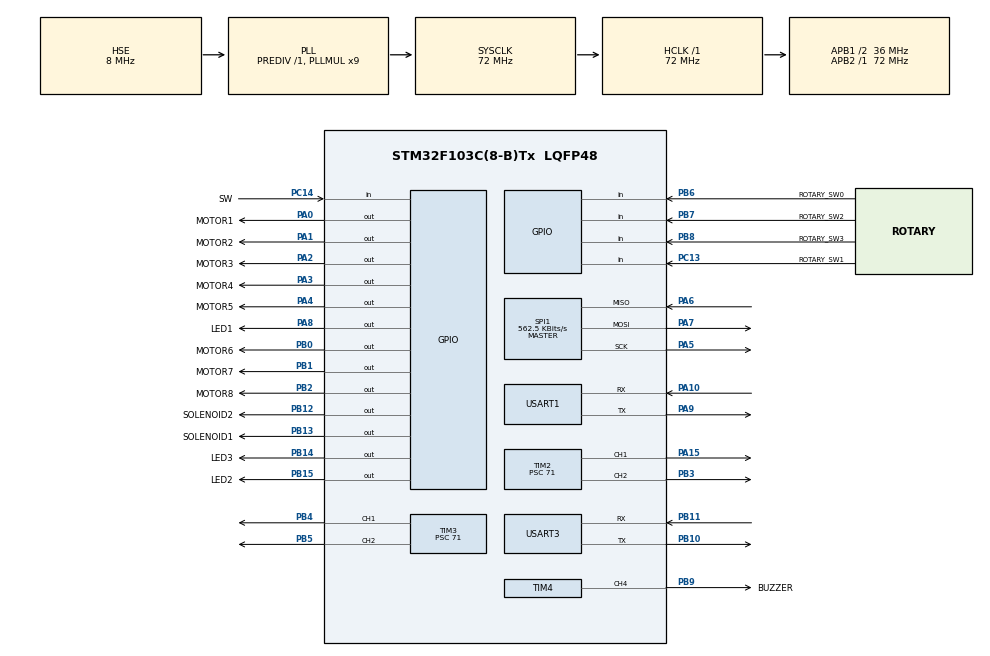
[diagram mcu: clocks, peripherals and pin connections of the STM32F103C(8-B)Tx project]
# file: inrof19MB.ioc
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Dma.Request0=USART3_RX
Dma.Request1=USART3_TX
Dma.Request2=USART1_RX
Dma.Request3=USART1_TX
Dma.USART1_RX.2.Direction=DMA_PERIPH_TO_MEMORY
Dma.USART1_RX.2.Instance=DMA1_Channel5
Dma.USART1_RX.2.MemDataAlignment=DMA_MDATAALIGN_BYTE
Dma.USART1_RX.2.MemInc=DMA_MINC_ENABLE
Dma.USART1_RX.2.Mode=DMA_CIRCULAR
Dma.USART1_RX.2.PeriphDataAlignment=DMA_PDATAALIGN_BYTE
Dma.USART1_RX.2.PeriphInc=DMA_PINC_DISABLE
Dma.USART1_RX.2.Priority=DMA_PRIORITY_LOW
Dma.USART1_TX.3.Direction=DMA_MEMORY_TO_PERIPH
Dma.USART1_TX.3.Instance=DMA1_Channel4
Dma.USART1_TX.3.MemDataAlignment=DMA_MDATAALIGN_BYTE
Dma.USART1_TX.3.MemInc=DMA_MINC_ENABLE
Dma.USART1_TX.3.Mode=DMA_NORMAL
Dma.USART1_TX.3.PeriphDataAlignment=DMA_PDATAALIGN_BYTE
Dma.USART1_TX.3.PeriphInc=DMA_PINC_DISABLE
Dma.USART1_TX.3.Priority=DMA_PRIORITY_LOW
Dma.USART3_RX.0.Direction=DMA_PERIPH_TO_MEMORY
Dma.USART3_RX.0.Instance=DMA1_Channel3
Dma.USART3_RX.0.MemDataAlignment=DMA_MDATAALIGN_BYTE
Dma.USART3_RX.0.MemInc=DMA_MINC_ENABLE
Dma.USART3_RX.0.Mode=DMA_NORMAL
Dma.USART3_RX.0.PeriphDataAlignment=DMA_PDATAALIGN_BYTE
Dma.USART3_RX.0.PeriphInc=DMA_PINC_DISABLE
Dma.USART3_RX.0.Priority=DMA_PRIORITY_LOW
Dma.USART3_TX.1.Direction=DMA_MEMORY_TO_PERIPH
Dma.USART3_TX.1.Instance=DMA1_Channel2
Dma.USART3_TX.1.MemDataAlignment=DMA_MDATAALIGN_BYTE
Dma.USART3_TX.1.MemInc=DMA_MINC_ENABLE
Dma.USART3_TX.1.Mode=DMA_NORMAL
Dma.USART3_TX.1.PeriphDataAlignment=DMA_PDATAALIGN_BYTE
Dma.USART3_TX.1.PeriphInc=DMA_PINC_DISABLE
Dma.USART3_TX.1.Priority=DMA_PRIORITY_LOW
Mcu.Family=STM32F1
Mcu.Name=STM32F103C(8-B)Tx
Mcu.Package=LQFP48
NVIC.DMA1_Channel2_IRQn=true\:0\:0\:false\:false\:true\:false
NVIC.DMA1_Channel3_IRQn=true\:0\:0\:false\:false\:true\:false
NVIC.DMA1_Channel4_IRQn=true\:0\:0\:false\:false\:true\:false
NVIC.DMA1_Channel5_IRQn=true\:0\:0\:false\:false\:true\:false
NVIC.PriorityGroup=NVIC_PRIORITYGROUP_4
NVIC.TIM1_UP_IRQn=true\:0\:0\:false\:false\:true\:true
NVIC.USART1_IRQn=true\:0\:0\:false\:false\:true\:true
PA0-WKUP.GPIO_Label=MOTOR1
PA0-WKUP.Signal=GPIO_Output
PA1.GPIO_Label=MOTOR2
PA1.Signal=GPIO_Output
PA10.Mode=Asynchronous
PA10.Signal=USART1_RX
PA13.Mode=Serial_Wire
PA13.Signal=SYS_JTMS-SWDIO
PA14.Mode=Serial_Wire
PA14.Signal=SYS_JTCK-SWCLK
PA15.Signal=S_TIM2_CH1_ETR
PA2.GPIO_Label=MOTOR3
PA2.Signal=GPIO_Output
PA3.GPIO_Label=MOTOR4
PA3.Signal=GPIO_Output
PA4.GPIO_Label=MOTOR5
PA4.Signal=GPIO_Output
PA5.Mode=Full_Duplex_Master
PA5.Signal=SPI1_SCK
PA6.Mode=Full_Duplex_Master
PA6.Signal=SPI1_MISO
PA7.Mode=Full_Duplex_Master
PA7.Signal=SPI1_MOSI
PA8.GPIO_Label=LED1
PA8.Signal=GPIO_Output
PA9.Mode=Asynchronous
PA9.Signal=USART1_TX
PB0.GPIO_Label=MOTOR6
PB0.Signal=GPIO_Output
PB1.GPIO_Label=MOTOR7
PB1.Signal=GPIO_Output
PB10.Mode=Asynchronous
PB10.Signal=USART3_TX
PB11.Mode=Asynchronous
PB11.Signal=USART3_RX
PB12.GPIO_Label=SOLENOID2
PB12.Signal=GPIO_Output
PB13.GPIO_Label=SOLENOID1
PB13.Signal=GPIO_Output
PB14.GPIO_Label=LED3
PB14.Signal=GPIO_Output
PB15.GPIO_Label=LED2
PB15.Signal=GPIO_Output
PB2.GPIO_Label=MOTOR8
PB2.Signal=GPIO_Output
PB3.Signal=S_TIM2_CH2
PB4.Signal=S_TIM3_CH1
PB5.Signal=S_TIM3_CH2
PB6.GPIO_Label=ROTARY_SW0
PB6.Signal=GPIO_Input
PB7.GPIO_Label=ROTARY_SW2
PB7.Signal=GPIO_Input
PB8.GPIO_Label=ROTARY_SW3
PB8.Signal=GPIO_Input
PB9.GPIO_Label=BUZZER
PB9.Signal=S_TIM4_CH4
PC13-TAMPER-RTC.GPIO_Label=ROTARY_SW1
PC13-TAMPER-RTC.Signal=GPIO_Input
PC14-OSC32_IN.GPIO_Label=SW
PC14-OSC32_IN.Signal=GPIO_Input
PD0-OSC_IN.Mode=HSE-External-Oscillator
PD0-OSC_IN.Signal=RCC_OSC_IN
PD1-OSC_OUT.Mode=HSE-External-Oscillator
PD1-OSC_OUT.Signal=RCC_OSC_OUT
ProjectManager.HeapSize=0x200
ProjectManager.StackSize=0x400
ProjectManager.TargetToolchain=SW4STM32
RCC.AHBFreq_Value=72000000
RCC.APB1CLKDivider=RCC_HCLK_DIV2
RCC.APB1Freq_Value=36000000
RCC.APB1TimFreq_Value=72000000
RCC.APB2Freq_Value=72000000
RCC.APB2TimFreq_Value=72000000
RCC.HCLKFreq_Value=72000000
RCC.PLLMUL=RCC_PLL_MUL9
RCC.PLLSourceVirtual=RCC_PLLSOURCE_HSE
RCC.SYSCLKFreq_VALUE=72000000
RCC.SYSCLKSource=RCC_SYSCLKSOURCE_PLLCLK
RCC.USBFreq_Value=72000000
SH.S_TIM2_CH1_ETR.0=TIM2_CH1,PWM Generation1 CH1
SH.S_TIM2_CH2.0=TIM2_CH2,PWM Generation2 CH2
SH.S_TIM3_CH1.0=TIM3_CH1,PWM Generation1 CH1
SH.S_TIM3_CH2.0=TIM3_CH2,PWM Generation2 CH2
SH.S_TIM4_CH4.0=TIM4_CH4,PWM Generation4 CH4
SPI1.BaudRatePrescaler=SPI_BAUDRATEPRESCALER_128
SPI1.CalculateBaudRate=562.5 KBits/s
SPI1.Direction=SPI_DIRECTION_2LINES
SPI1.Mode=SPI_MODE_MASTER
SPI1.VirtualType=VM_MASTER
TIM1.Period=7200-1
TIM1.Prescaler=100-1
TIM2.Channel-PWM\ Generation1\ CH1=TIM_CHANNEL_1
TIM2.Channel-PWM\ Generation2\ CH2=TIM_CHANNEL_2
TIM2.Period=19999
TIM2.Prescaler=71
TIM3.Channel-PWM\ Generation1\ CH1=TIM_CHANNEL_1
TIM3.Channel-PWM\ Generation2\ CH2=TIM_CHANNEL_2
TIM3.Period=19999
TIM3.Prescaler=71
TIM4.Channel-PWM\ Generation4\ CH4=TIM_CHANNEL_4
TIM4.Period=999
TIM4.Prescaler=100
TIM4.Pulse-PWM\ Generation4\ CH4=500
USART1.VirtualMode=VM_ASYNC
USART3.VirtualMode=VM_ASYNC
VP_TIM1_VS_ClockSourceINT.Mode=Internal
board=custom

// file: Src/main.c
/* USER CODE BEGIN Header */
/**
  ******************************************************************************
  * @file           : main.c
  * @brief          : Main program body
  ******************************************************************************
  ** This notice applies to any and all portions of this file
  * that are not between comment pairs USER CODE BEGIN and
  * USER CODE END. Other portions of this file, whether
  * inserted by the user or by software development tools
  * are owned by their respective copyright owners.
  *
  * COPYRIGHT(c) 2019 STMicroelectronics
  *
  * Redistribution and use in source and binary forms, with or without modification,
  * are permitted provided that the following conditions are met:
  *   1. Redistributions of source code must retain the above copyright notice,
  *      this list of conditions and the following disclaimer.
  *   2. Redistributions in binary form must reproduce the above copyright notice,
  *      this list of conditions and the following disclaimer in the documentation
  *      and/or other materials provided with the distribution.
  *   3. Neither the name of STMicroelectronics nor the names of its contributors
  *      may be used to endorse or promote products derived from this software
  *      without specific prior written permission.
  *
  * THIS SOFTWARE IS PROVIDED BY THE COPYRIGHT HOLDERS AND CONTRIBUTORS "AS IS"
  * AND ANY EXPRESS OR IMPLIED WARRANTIES, INCLUDING, BUT NOT LIMITED TO, THE
  * IMPLIED WARRANTIES OF MERCHANTABILITY AND FITNESS FOR A PARTICULAR PURPOSE ARE
  * DISCLAIMED. IN NO EVENT SHALL THE COPYRIGHT HOLDER OR CONTRIBUTORS BE LIABLE
  * FOR ANY DIRECT, INDIRECT, INCIDENTAL, SPECIAL, EXEMPLARY, OR CONSEQUENTIAL
  * DAMAGES (INCLUDING, BUT NOT LIMITED TO, PROCUREMENT OF SUBSTITUTE GOODS OR
  * SERVICES; LOSS OF USE, DATA, OR PROFITS; OR BUSINESS INTERRUPTION) HOWEVER
  * CAUSED AND ON ANY THEORY OF LIABILITY, WHETHER IN CONTRACT, STRICT LIABILITY,
  * OR TORT (INCLUDING NEGLIGENCE OR OTHERWISE) ARISING IN ANY WAY OUT OF THE USE
  * OF THIS SOFTWARE, EVEN IF ADVISED OF THE POSSIBILITY OF SUCH DAMAGE.
  *
  ******************************************************************************
  */
/* USER CODE END Header */

#include "main.h"
#include "dma.h"
#include "spi.h"
#include "tim.h"
#include "usart.h"
#include "gpio.h"

/* USER CODE BEGIN Includes */
#include "main_func.h"
/* USER CODE END Includes */

void SystemClock_Config(void);

int main(void)
{

  /* MCU Configuration--------------------------------------------------------*/

  /* Reset of all peripherals, Initializes the Flash interface and the Systick. */
  HAL_Init();

  /* Configure the system clock */
  SystemClock_Config();

  /* Initialize all configured peripherals */
  MX_GPIO_Init();
  MX_DMA_Init();
  MX_USART1_UART_Init();
  MX_TIM1_Init();
  MX_SPI1_Init();
  MX_USART3_UART_Init();
  MX_TIM2_Init();
  MX_TIM3_Init();
  MX_TIM4_Init();
  /* USER CODE BEGIN 2 */

  Init();

  /* USER CODE END 2 */

  /* Infinite loop */
  while (1)
  {

    /* USER CODE BEGIN 3 */
	Loop();

  }
  /* USER CODE END 3 */
}

void SystemClock_Config(void)
{
  RCC_OscInitTypeDef RCC_OscInitStruct = {0};
  RCC_ClkInitTypeDef RCC_ClkInitStruct = {0};

  /**Initializes the CPU, AHB and APB busses clocks
  */
  RCC_OscInitStruct.OscillatorType = RCC_OSCILLATORTYPE_HSE;
  RCC_OscInitStruct.HSEState = RCC_HSE_ON;
  RCC_OscInitStruct.HSEPredivValue = RCC_HSE_PREDIV_DIV1;
  RCC_OscInitStruct.HSIState = RCC_HSI_ON;
  RCC_OscInitStruct.PLL.PLLState = RCC_PLL_ON;
  RCC_OscInitStruct.PLL.PLLSource = RCC_PLLSOURCE_HSE;
  RCC_OscInitStruct.PLL.PLLMUL = RCC_PLL_MUL9;
  if (HAL_RCC_OscConfig(&RCC_OscInitStruct) != HAL_OK)
  {
    Error_Handler();
  }
  /**Initializes the CPU, AHB and APB busses clocks
  */
  RCC_ClkInitStruct.ClockType = RCC_CLOCKTYPE_HCLK|RCC_CLOCKTYPE_SYSCLK
                              |RCC_CLOCKTYPE_PCLK1|RCC_CLOCKTYPE_PCLK2;
  RCC_ClkInitStruct.SYSCLKSource = RCC_SYSCLKSOURCE_PLLCLK;
  RCC_ClkInitStruct.AHBCLKDivider = RCC_SYSCLK_DIV1;
  RCC_ClkInitStruct.APB1CLKDivider = RCC_HCLK_DIV2;
  RCC_ClkInitStruct.APB2CLKDivider = RCC_HCLK_DIV1;

  if (HAL_RCC_ClockConfig(&RCC_ClkInitStruct, FLASH_LATENCY_2) != HAL_OK)
  {
    Error_Handler();
  }
}

void Error_Handler(void)
{
}

/************************ (C) COPYRIGHT STMicroelectronics *****END OF FILE****/
